AUTOSAR XML (schema 314)
package /ComponentType
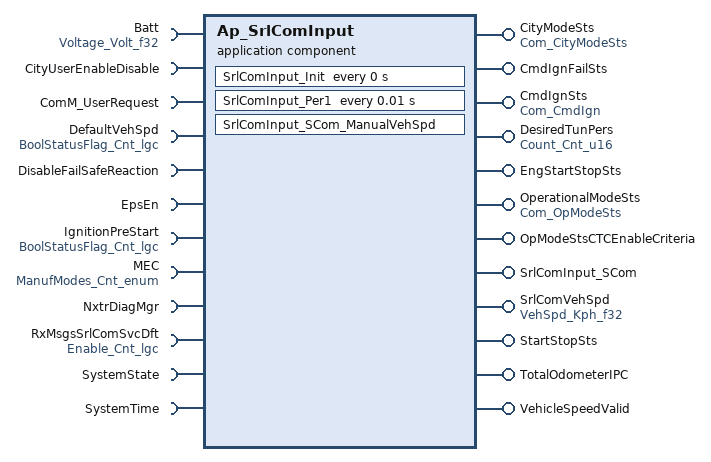
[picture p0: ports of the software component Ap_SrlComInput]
  application software component type Ap_SrlComInput
    12 x provide port:
      CityModeSts: unqueued-sender-com-spec{data-element=Cnt_lgc, can-invalidate=false, init-value=D_FALSE_CNT_LGC}, provided-interface=Com_CityModeSts
      CmdIgnFailSts: unqueued-sender-com-spec{data-element=Cnt_u8, can-invalidate=false, init-value=C_CmdIgn_FailSts}, provided-interface=CmdIgnFailSts
      CmdIgnSts: unqueued-sender-com-spec{data-element=Cnt_u16, can-invalidate=false, init-value=C_CmdIgnSts}, provided-interface=Com_CmdIgn
      DesiredTunPers: unqueued-sender-com-spec{data-element=Cnt_u16, can-invalidate=false, init-value=D_ZERO_CNT_U16}, provided-interface=Count_Cnt_u16
      EngStartStopSts: unqueued-sender-com-spec{data-element=Cnt_u8, can-invalidate=false, init-value=D_ZERO_CNT_U8}, provided-interface=EngStartStopSts
      OperationalModeSts: unqueued-sender-com-spec{data-element=Cnt_u16, can-invalidate=false, init-value=C_OperationalModeSts}, provided-interface=Com_OpModeSts
      OpModeStsCTCEnableCriteria: unqueued-sender-com-spec{data-element=Cnt_lgc, can-invalidate=false, init-value=D_FALSE_CNT_LGC}, provided-interface=OpModeStsCTCEnableCriteria
      SrlComInput_SCom: server-com-spec{operation=ManualVehSpd, queue-length=1}, provided-interface=SrlComInput_SCom
      SrlComVehSpd: unqueued-sender-com-spec{data-element=Kph_f32, can-invalidate=false, init-value=D_ZERO_ULS_F32}, provided-interface=VehSpd_Kph_f32
      StartStopSts: unqueued-sender-com-spec{data-element=Cnt_u8, can-invalidate=false, init-value=D_ZERO_CNT_U8}, provided-interface=StartStopSts
      TotalOdometerIPC: unqueued-sender-com-spec{data-element=Cnt_u32, can-invalidate=false, init-value=D_ZERO_CNT_U32}, provided-interface=TotalOdometerIPC
      VehicleSpeedValid: unqueued-sender-com-spec{data-element=Cnt_lgc, can-invalidate=false, init-value=D_FALSE_CNT_LGC}, provided-interface=VehicleSpeedValid
    12 x require port:
      Batt: unqueued-receiver-com-spec{data-element=Volt_f32, init-value=D_ZERO_ULS_F32}, required-interface=Voltage_Volt_f32
      CityUserEnableDisable: unqueued-receiver-com-spec{data-element=Cnt_enum, init-value=D_CITYUSERENABLEDISABLE_ENUM}, required-interface=CityUserEnableDisable
      ComM_UserRequest: required-com-specs=[GetCurrentComMode, GetMaxComMode, GetRequestedMode, RequestComMode], required-interface=ComM_UserRequest
      DefaultVehSpd: unqueued-receiver-com-spec{data-element=Cnt_lgc, init-value=D_FALSE_CNT_LGC}, required-interface=BoolStatusFlag_Cnt_lgc
      DisableFailSafeReaction: unqueued-receiver-com-spec{data-element=Cnt_lgc, init-value=D_FALSE_CNT_LGC}, required-interface=DisableFailSafeReaction
      EpsEn: client-com-spec=OP_GET, required-interface=EpsEn
      IgnitionPreStart: unqueued-receiver-com-spec{data-element=Cnt_lgc, init-value=D_FALSE_CNT_LGC}, required-interface=BoolStatusFlag_Cnt_lgc
      MEC: unqueued-receiver-com-spec{data-element=Cnt_enum, init-value=D_MANUFMODEINIT_CNT_ENUM}, required-interface=ManufModes_Cnt_enum
      NxtrDiagMgr: required-com-specs=[GetNTCActive, GetNTCFailed, GetNTCStatus, SetNTCStatus], required-interface=NxtrDiagMgr
      RxMsgsSrlComSvcDft: unqueued-receiver-com-spec{data-element=Cnt_lgc, init-value=D_FALSE_CNT_LGC}, required-interface=Enable_Cnt_lgc
      SystemState: required-interface=SystemState
      SystemTime: required-interface=SystemTime
        required-com-specs:
          DtrmnElapsedTime_mS_u16
          DtrmnElapsedTime_mS_u32
          DtrmnElapsedTime_uS_u16
          DtrmnElapsedTime_uS_u32
          GetSystemTime_mS_u32
          GetSystemTime_uS_u32
  internal behavior Ap_SrlComInput_InternalBehavior: component=Ap_SrlComInput
    timing event SrlComInput_InitEvent: start-on-event=SrlComInput_Init, period=0
    timing event TMT_SrlComInput_Per1: start-on-event=SrlComInput_Per1, period=0.01
    operation invoked event OIT_SrlComInput_SCom_ManualVehSpd_SrlComInput_SCom_ManualVehSpd: start-on-event=SrlComInput_SCom_ManualVehSpd, operation=SrlComInput_SCom.ManualVehSpd
    port-api-options:
      enable-take-address=false, indirect-api=false, port=Batt
      enable-take-address=false, indirect-api=false, port=CityModeSts
      enable-take-address=false, indirect-api=false, port=CityUserEnableDisable
      enable-take-address=false, indirect-api=false, port=CmdIgnFailSts
      enable-take-address=false, indirect-api=false, port=CmdIgnSts
      enable-take-address=false, indirect-api=false, port=ComM_UserRequest
      enable-take-address=false, indirect-api=false, port=DefaultVehSpd
      enable-take-address=false, indirect-api=false, port=DesiredTunPers
      enable-take-address=false, indirect-api=false, port=DisableFailSafeReaction
      enable-take-address=false, indirect-api=false, port=EngStartStopSts
      enable-take-address=false, indirect-api=false, port=EpsEn
      enable-take-address=false, indirect-api=false, port=IgnitionPreStart
      enable-take-address=false, indirect-api=false, port=MEC
      enable-take-address=false, indirect-api=false, port=NxtrDiagMgr
      enable-take-address=false, indirect-api=false, port=OperationalModeSts
      enable-take-address=false, indirect-api=false, port=OpModeStsCTCEnableCriteria
      enable-take-address=false, indirect-api=false, port=RxMsgsSrlComSvcDft
      enable-take-address=false, indirect-api=false, port=SrlComInput_SCom
      enable-take-address=false, indirect-api=false, port=SrlComVehSpd
      enable-take-address=false, indirect-api=false, port=StartStopSts
      enable-take-address=false, indirect-api=false, port=SystemState
      enable-take-address=false, indirect-api=false, port=SystemTime
      enable-take-address=false, indirect-api=false, port=TotalOdometerIPC
      enable-take-address=false, indirect-api=false, port=VehicleSpeedValid
    runnable SrlComInput_Init
      sync call SC_SystemTime_GetSystemTime_mS_u32: operation=SystemTime.GetSystemTime_mS_u32, timeout=0
    runnable SrlComInput_Per1
      7 x data read access:
        READ_Batt_Volt_f32: data-element=Batt.Volt_f32
        READ_CityUserEnableDisable_Cnt_enum: data-element=CityUserEnableDisable.Cnt_enum
        READ_DefaultVehSpd_Cnt_lgc: data-element=DefaultVehSpd.Cnt_lgc
        READ_DisableFailSafeReaction_Cnt_lgc: data-element=DisableFailSafeReaction.Cnt_lgc
        READ_IgnitionPreStart_Cnt_lgc: data-element=IgnitionPreStart.Cnt_lgc
        READ_MEC_Cnt_enum: data-element=MEC.Cnt_enum
        READ_RxMsgsSrlComSvcDft_Cnt_lgc: data-element=RxMsgsSrlComSvcDft.Cnt_lgc
      11 x data write access:
        WRITE_CityModeSts_Cnt_lgc: data-element=CityModeSts.Cnt_lgc
        WRITE_CmdIgnFailSts_Cnt_u8: data-element=CmdIgnFailSts.Cnt_u8
        WRITE_CmdIgnSts_Cnt_u16: data-element=CmdIgnSts.Cnt_u16
        WRITE_DesiredTunPers_Cnt_u16: data-element=DesiredTunPers.Cnt_u16
        WRITE_EngStartStopSts_Cnt_u8: data-element=EngStartStopSts.Cnt_u8
        WRITE_OperationalModeSts_Cnt_u16: data-element=OperationalModeSts.Cnt_u16
        WRITE_OpModeStsCTCEnableCriteria_Cnt_lgc: data-element=OpModeStsCTCEnableCriteria.Cnt_lgc
        WRITE_SrlComVehSpd_Kph_f32: data-element=SrlComVehSpd.Kph_f32
        WRITE_StartStopSts_Cnt_u8: data-element=StartStopSts.Cnt_u8
        WRITE_TotalOdometerIPC_Cnt_u32: data-element=TotalOdometerIPC.Cnt_u32
        WRITE_VehicleSpeedValid_Cnt_lgc: data-element=VehicleSpeedValid.Cnt_lgc
      6 x sync call, all with timeout=0:
        SC_ComM_UserRequest_RequestComMode: operation=ComM_UserRequest.RequestComMode
        SC_EpsEn_OP_GET: operation=EpsEn.OP_GET
        SC_NxtrDiagMgr_GetNTCFailed: operation=NxtrDiagMgr.GetNTCFailed
        SC_NxtrDiagMgr_SetNTCStatus: operation=NxtrDiagMgr.SetNTCStatus
        SC_SystemTime_DtrmnElapsedTime_mS_u16: operation=SystemTime.DtrmnElapsedTime_mS_u16
        SC_SystemTime_GetSystemTime_mS_u32: operation=SystemTime.GetSystemTime_mS_u32
    runnable SrlComInput_SCom_ManualVehSpd
  swc implementation Ap_SrlComInput_Implementation: behavior=Ap_SrlComInput_InternalBehavior
    code-descriptors:
      code Code: type=SRC
